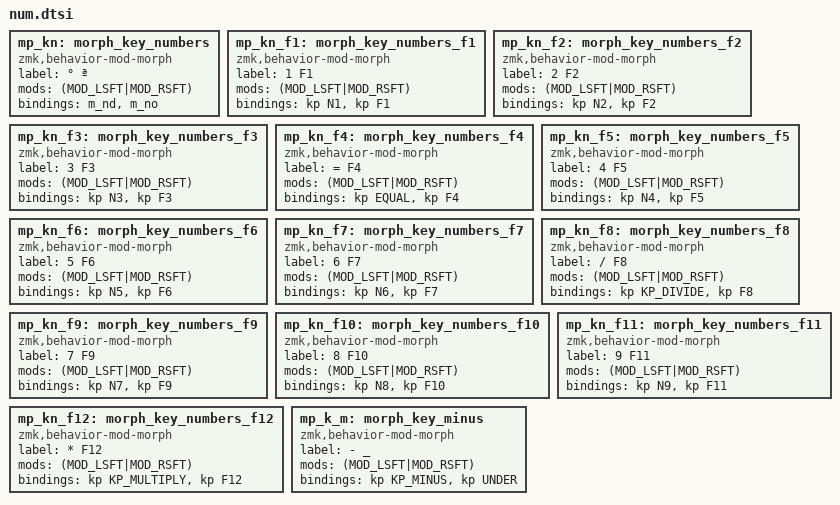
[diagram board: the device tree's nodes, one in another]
mp_kn: morph_key_numbers {
    compatible = "zmk,behavior-mod-morph";
    label = "° ª";
    #binding-cells = <0>;
    mods = <(MOD_LSFT|MOD_RSFT)>;
    bindings = <&m_nd>, <&m_no>;
};

mp_kn_f1: morph_key_numbers_f1 {
    compatible = "zmk,behavior-mod-morph";
    label = "1 F1";
    #binding-cells = <0>;
    mods = <(MOD_LSFT|MOD_RSFT)>;
    bindings = <&kp N1>, <&kp F1>;
};

mp_kn_f2: morph_key_numbers_f2 {
    compatible = "zmk,behavior-mod-morph";
    label = "2 F2";
    #binding-cells = <0>;
    mods = <(MOD_LSFT|MOD_RSFT)>;
    bindings = <&kp N2>, <&kp F2>;
};

mp_kn_f3: morph_key_numbers_f3 {
    compatible = "zmk,behavior-mod-morph";
    label = "3 F3";
    #binding-cells = <0>;
    mods = <(MOD_LSFT|MOD_RSFT)>;
    bindings = <&kp N3>, <&kp F3>;
};

mp_kn_f4: morph_key_numbers_f4 {
    compatible = "zmk,behavior-mod-morph";
    label = "= F4";
    #binding-cells = <0>;
    mods = <(MOD_LSFT|MOD_RSFT)>;
    bindings = <&kp EQUAL>, <&kp F4>;
};

mp_kn_f5: morph_key_numbers_f5 {
    compatible = "zmk,behavior-mod-morph";
    label = "4 F5";
    #binding-cells = <0>;
    mods = <(MOD_LSFT|MOD_RSFT)>;
    bindings = <&kp N4>, <&kp F5>;
};

mp_kn_f6: morph_key_numbers_f6 {
    compatible = "zmk,behavior-mod-morph";
    label = "5 F6";
    #binding-cells = <0>;
    mods = <(MOD_LSFT|MOD_RSFT)>;
    bindings = <&kp N5>, <&kp F6>;
};

mp_kn_f7: morph_key_numbers_f7 {
    compatible = "zmk,behavior-mod-morph";
    label = "6 F7";
    #binding-cells = <0>;
    mods = <(MOD_LSFT|MOD_RSFT)>;
    bindings = <&kp N6>, <&kp F7>;
};

mp_kn_f8: morph_key_numbers_f8 {
    compatible = "zmk,behavior-mod-morph";
    label = "/ F8";
    #binding-cells = <0>;
    mods = <(MOD_LSFT|MOD_RSFT)>;
    bindings = <&kp KP_DIVIDE>, <&kp F8>;
};

mp_kn_f9: morph_key_numbers_f9 {
    compatible = "zmk,behavior-mod-morph";
    label = "7 F9";
    #binding-cells = <0>;
    mods = <(MOD_LSFT|MOD_RSFT)>;
    bindings = <&kp N7>, <&kp F9>;
};

mp_kn_f10: morph_key_numbers_f10 {
    compatible = "zmk,behavior-mod-morph";
    label = "8 F10";
    #binding-cells = <0>;
    mods = <(MOD_LSFT|MOD_RSFT)>;
    bindings = <&kp N8>, <&kp F10>;
};

mp_kn_f11: morph_key_numbers_f11 {
    compatible = "zmk,behavior-mod-morph";
    label = "9 F11";
    #binding-cells = <0>;
    mods = <(MOD_LSFT|MOD_RSFT)>;
    bindings = <&kp N9>, <&kp F11>;
};

mp_kn_f12: morph_key_numbers_f12 {
    compatible = "zmk,behavior-mod-morph";
    label = "* F12";
    #binding-cells = <0>;
    mods = <(MOD_LSFT|MOD_RSFT)>;
    bindings = <&kp KP_MULTIPLY>, <&kp F12>;
};

mp_k_m: morph_key_minus {
    compatible = "zmk,behavior-mod-morph";
    label = "- _";
    #binding-cells = <0>;
    mods = <(MOD_LSFT|MOD_RSFT)>;
    bindings = <&kp KP_MINUS>, <&kp UNDER>;
};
